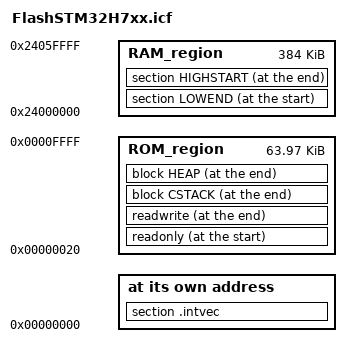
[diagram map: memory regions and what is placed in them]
/*###ICF### Section handled by ICF editor, don't touch! ****/
/*-Editor annotation file-*/
/* IcfEditorFile="$TOOLKIT_DIR$\config\ide\IcfEditor\cortex_v1_0.xml" */
/*-Specials-*/
define symbol __ICFEDIT_intvec_start__ = 0x00000000;
/*-Memory Regions-*/
define symbol __ICFEDIT_region_ROM_start__ = 0x00000020;
define symbol __ICFEDIT_region_ROM_end__   = 0x0000FFFF;
define symbol __ICFEDIT_region_RAM_start__ = 0x24000000;
define symbol __ICFEDIT_region_RAM_end__   = 0x2405FFFF;
/*-Sizes-*/
define symbol __ICFEDIT_size_cstack__ = 0x400;
define symbol __ICFEDIT_size_heap__   = 0x000;
/**** End of ICF editor section. ###ICF###*/


define memory mem with size = 4G;
define region ROM_region   = mem:[from __ICFEDIT_region_ROM_start__   to __ICFEDIT_region_ROM_end__];
define region RAM_region   = mem:[from __ICFEDIT_region_RAM_start__   to __ICFEDIT_region_RAM_end__];

define block CSTACK    with alignment = 8, size = __ICFEDIT_size_cstack__   { };
define block HEAP      with alignment = 8, size = __ICFEDIT_size_heap__     { };

//initialize by copy { readwrite };
do not initialize  { section .noinit };
do not initialize {readwrite };
place at address mem:__ICFEDIT_intvec_start__ { section .intvec };

place at start of ROM_region { readonly };
place at end of ROM_region   { readwrite, block CSTACK, block HEAP};

place at start of RAM_region { section LOWEND };
place at end of RAM_region   { section HIGHSTART};
